AUTOSAR XML (schema 4-0-3)
standard types defined: uint8, Boolean, UInt16, UInt32, UInt8
package /AUTOSAR_Platform/DataConstrs
  range DC_Boolean: raw 0..1
  range DC_UInt16: raw 0..65535
  range DC_UInt8: raw 0..255
package /PATAC/Facility/DataTypes/Implementation
  compu method COMPU_Boolean: 0=FALSE, 1=TRUE
  unit NoUnit: factor-si-to-unit=1, offset-si-to-unit=0
package /PATAC/MSM/ComponentTypes
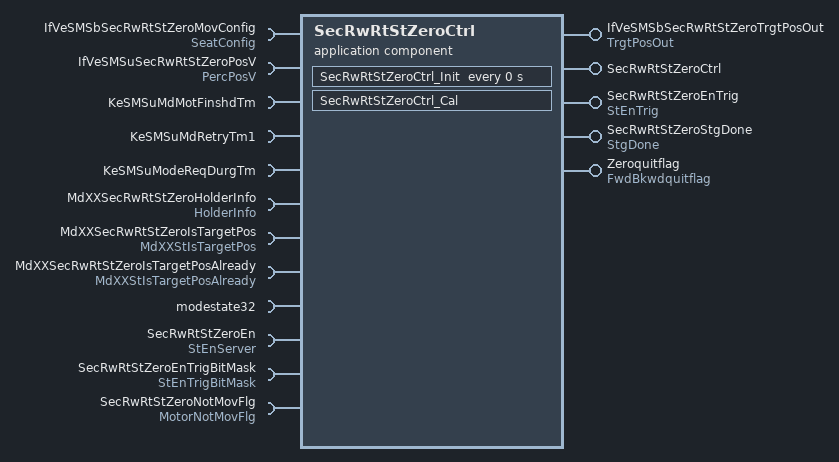
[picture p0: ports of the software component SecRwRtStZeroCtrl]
  application sw component type SecRwRtStZeroCtrl
    5 x provide port:
      IfVeSMSbSecRwRtStZeroTrgtPosOut: nonqueued-sender-com-spec{data-element=TrgtPosOut/Val, init-value=0}, provided-interface=TrgtPosOut
      SecRwRtStZeroCtrl: server-com-spec{operation=Cal, queue-length=1}, provided-interface=SecRwRtStZeroCtrl
      SecRwRtStZeroEnTrig: nonqueued-sender-com-spec{data-element=StEnTrig/Val, init-value=0}, provided-interface=StEnTrig
      SecRwRtStZeroStgDone: nonqueued-sender-com-spec{data-element=StgDone/Val, init-value=0}, provided-interface=StgDone
      Zeroquitflag: nonqueued-sender-com-spec{data-element=FwdBkwdquitflag/Val, init-value=0}, provided-interface=FwdBkwdquitflag
    12 x require port:
      IfVeSMSbSecRwRtStZeroMovConfig: nonqueued-receiver-com-spec{data-element=SeatConfig/Val, filter=data-filter-type=ALWAYS, init-value=0}, required-interface=SeatConfig
      IfVeSMSuSecRwRtStZeroPosV: nonqueued-receiver-com-spec{data-element=PercPosV/Val, filter=data-filter-type=ALWAYS, init-value=0}, required-interface=PercPosV
      KeSMSuMdMotFinshdTm: parameter-require-com-spec{init-value=0, parameter=KeSMSuMdMotFinshdTm/Val}, required-interface=KeSMSuMdMotFinshdTm
      KeSMSuMdRetryTm1: parameter-require-com-spec{init-value=0, parameter=KeSMSuMdRetryTm1/Val}, required-interface=KeSMSuMdRetryTm1
      KeSMSuModeReqDurgTm: parameter-require-com-spec{init-value=0, parameter=KeSMSuModeReqDurgTm/Val}, required-interface=KeSMSuModeReqDurgTm
      MdXXSecRwRtStZeroHolderInfo: nonqueued-receiver-com-spec{data-element=HolderInfo/Val, filter=data-filter-type=ALWAYS, init-value=0}, required-interface=HolderInfo
      MdXXSecRwRtStZeroIsTargetPos: nonqueued-receiver-com-spec{data-element=MdXXStIsTargetPos/Val, filter=data-filter-type=ALWAYS, init-value=0}, required-interface=MdXXStIsTargetPos
      MdXXSecRwRtStZeroIsTargetPosAlready: nonqueued-receiver-com-spec{data-element=MdXXStIsTargetPosAlready/Val, filter=data-filter-type=ALWAYS, init-value=0}, required-interface=MdXXStIsTargetPosAlready
      modestate32: nonqueued-receiver-com-spec{data-element=modestate32/Val, filter=data-filter-type=ALWAYS, init-value=0}, required-interface=modestate32
      SecRwRtStZeroEn: required-com-specs=[Clear, Get, Set], required-interface=StEnServer
      SecRwRtStZeroEnTrigBitMask: nonqueued-receiver-com-spec{data-element=StEnTrigBitMask/Val, filter=data-filter-type=ALWAYS, init-value=0}, required-interface=StEnTrigBitMask
      SecRwRtStZeroNotMovFlg: nonqueued-receiver-com-spec{data-element=MotorNotMovFlg/Val, filter=data-filter-type=ALWAYS, init-value=0}, required-interface=MotorNotMovFlg
    behavior SecRwRtStZeroCtrl_InternalBehavior
      operation invoked event OIT_SecRwRtStZeroCtrl_Cal_SecRwRtStZeroCtrl_Cal: start-on-event=SecRwRtStZeroCtrl_Cal, operation=SecRwRtStZeroCtrl.Cal
      timing event SecRwRtStZeroCtrl_InitEvent: start-on-event=SecRwRtStZeroCtrl_Init, period=0
      runnable SecRwRtStZeroCtrl_Cal
        data-receive-point-by-arguments:
          8 x access:
            REC_IfVeSMSbSecRwRtStZeroMovConfig_Val: accessed-variable=IfVeSMSbSecRwRtStZeroMovConfig.Val
            REC_IfVeSMSuSecRwRtStZeroPosV_Val: accessed-variable=IfVeSMSuSecRwRtStZeroPosV.Val
            REC_MdXXSecRwRtStZeroHolderInfo_Val: accessed-variable=MdXXSecRwRtStZeroHolderInfo.Val
            REC_MdXXSecRwRtStZeroIsTargetPos_Val: accessed-variable=MdXXSecRwRtStZeroIsTargetPos.Val
            REC_MdXXSecRwRtStZeroIsTargetPosAlready_Val: accessed-variable=MdXXSecRwRtStZeroIsTargetPosAlready.Val
            REC_modestate32_Val: accessed-variable=modestate32.Val
            REC_SecRwRtStZeroEnTrigBitMask_Val: accessed-variable=SecRwRtStZeroEnTrigBitMask.Val
            REC_SecRwRtStZeroNotMovFlg_Val: accessed-variable=SecRwRtStZeroNotMovFlg.Val
        data-send-points:
          4 x access:
            SEND_IfVeSMSbSecRwRtStZeroTrgtPosOut_Val: accessed-variable=IfVeSMSbSecRwRtStZeroTrgtPosOut.Val
            SEND_SecRwRtStZeroEnTrig_Val: accessed-variable=SecRwRtStZeroEnTrig.Val
            SEND_SecRwRtStZeroStgDone_Val: accessed-variable=SecRwRtStZeroStgDone.Val
            SEND_Zeroquitflag_Val: accessed-variable=Zeroquitflag.Val
        parameter access PA_KeSMSuMdMotFinshdTm_Val: accessed-parameter=KeSMSuMdMotFinshdTm.Val
        parameter access PA_KeSMSuMdRetryTm1_Val: accessed-parameter=KeSMSuMdRetryTm1.Val
        parameter access PA_KeSMSuModeReqDurgTm_Val: accessed-parameter=KeSMSuModeReqDurgTm.Val
        sync call SC_SecRwRtStZeroEn_Get: operation=SecRwRtStZeroEn.Get, timeout=0
      runnable SecRwRtStZeroCtrl_Init
        parameter access PA_KeSMSuMdMotFinshdTm_Val: accessed-parameter=KeSMSuMdMotFinshdTm.Val
        parameter access PA_KeSMSuMdRetryTm1_Val: accessed-parameter=KeSMSuMdRetryTm1.Val
        parameter access PA_KeSMSuModeReqDurgTm_Val: accessed-parameter=KeSMSuModeReqDurgTm.Val
  swc implementation SecRwRtStZeroCtrl_Implementation: behavior=SecRwRtStZeroCtrl_InternalBehavior
    code-descriptors:
      code Default: artifact-descriptors=autosar-engineering-object={short-label=Default, category=SWSRC}
package /PATAC/MSM/ModeAdjust/CalPortInterface
  parameter interface KeSMSuMdMotFinshdTm
    parameter data prototype Val: sw-calibration-access=READ-WRITE, type=UInt16
  parameter interface KeSMSuModeReqDurgTm
    parameter data prototype Val: sw-calibration-access=READ-WRITE, type=UInt16
package /PATAC/MSM/ModeAdjust/PortInterface
  client server interface SecRwRtStZeroCtrl
    operation Cal
  client server interface StEnServer
    operation Clear
      arg data: type=UInt8, direction=IN, server-argument-impl-policy=USE-ARGUMENT-TYPE
    operation Get
      arg data: type=UInt32, direction=OUT, server-argument-impl-policy=USE-ARGUMENT-TYPE
    operation Set
      arg data: type=UInt8, direction=IN, server-argument-impl-policy=USE-ARGUMENT-TYPE
  11 x sender receiver interface:
    FwdBkwdquitflag: invalidation-policy{data-element=FwdBkwdquitflag/Val, handle-invalid=DONT-INVALIDATE}
      data Val: type=Boolean
    HolderInfo: invalidation-policy{data-element=HolderInfo/Val, handle-invalid=DONT-INVALIDATE}
      data Val: type=UInt32
    MdXXStIsTargetPos: invalidation-policy{data-element=MdXXStIsTargetPos/Val, handle-invalid=DONT-INVALIDATE}
      data Val: type=UInt32
    MdXXStIsTargetPosAlready: invalidation-policy{data-element=MdXXStIsTargetPosAlready/Val, handle-invalid=DONT-INVALIDATE}
      data Val: type=UInt32
    modestate32: invalidation-policy{data-element=modestate32/Val, handle-invalid=DONT-INVALIDATE}
      data Val: type=UInt32
    MotorNotMovFlg: invalidation-policy{data-element=MotorNotMovFlg/Val, handle-invalid=DONT-INVALIDATE}
      data Val: type=Boolean
    PercPosV: invalidation-policy{data-element=PercPosV/Val, handle-invalid=DONT-INVALIDATE}
      data Val: type=Boolean
    StEnTrig: invalidation-policy{data-element=StEnTrig/Val, handle-invalid=DONT-INVALIDATE}
      data Val: type=Boolean
    StEnTrigBitMask: invalidation-policy{data-element=StEnTrigBitMask/Val, handle-invalid=DONT-INVALIDATE}
      data Val: type=UInt32
    StgDone: invalidation-policy{data-element=StgDone/Val, handle-invalid=DONT-INVALIDATE}
      data Val: type=Boolean
    TrgtPosOut: invalidation-policy{data-element=TrgtPosOut/Val, handle-invalid=DONT-INVALIDATE}
      data Val: type=Boolean
package /PATAC/MSM/PortInterfaces
  parameter interface KeSMSuMdRetryTm1
    parameter data prototype Val: sw-calibration-access=READ-WRITE, type=UInt8
  sender receiver interface SeatConfig: invalidation-policy{data-element=SeatConfig/Val, handle-invalid=DONT-INVALIDATE}
    data Val: type=Boolean
